# MINI51DE_v1 register map
File version: 1.0
MINI51DE_v1 SVD file
Registers are 32-bit, read-write, reset 0x0 unless marked. A register's access mark holds for its fields unless they carry their own. Offsets are from the block's base; lines under a group give offsets from that group; [hi:lo] are bit positions; {n}, {i} and the like mark numbered series; 'fields as' and 'values as' point back to an identical list; <NAME> marks a mode.

## Memory map
0x40004000 WDT size 0x4 — WDT Register Map
0x40010000 TMR blocks up to offset 0x3C — TMR Register Map
0x40020000 I2C blocks up to offset 0x44 — I2C Register Map
0x40030000 SPI blocks up to offset 0x48 — SPI Register Map
0x40040000 PWM blocks up to offset 0x88 — PWM Register Map
0x40050000 UART size 0x34 — UART Register Map
0x400D0000 ACMP size 0x10 — ACMP Register Map
0x400E0000 ADC blocks up to offset 0x4C — ADC Register Map
0x50000000 GCR blocks up to offset 0x104 — GCR Register Map
0x50000200 CLK blocks up to offset 0x28 — CLK Register Map
0x50000300 INT size 0x88 — INT Register Map
0x50004000 GP blocks up to offset 0x2B8 — GPIO Register Map
0x5000C000 FMC blocks up to offset 0x44 — FMC Register Map
0xE000E000 SCS blocks up to offset 0xD24 — SCS Register Map

## INT — INT Register Map
Base 0x50000300
0x00 IRQ0_SRC ro reset not defined — IRQ0 (BOD) Interrupt Source Identity
  [2:0] INT_SRC — Interrupt Source. Define the interrupt sources for interrupt event.
0x04 IRQ1_SRC ro reset not defined — IRQ1 (WDT) Interrupt Source Identity
  fields as IRQ0_SRC
0x08 IRQ2_SRC ro reset not defined — IRQ2 (EINT0) Interrupt Source Identity
  fields as IRQ0_SRC
0x0C IRQ3_SRC ro reset not defined — IRQ3 (EINT1) Interrupt Source Identity
  fields as IRQ0_SRC
0x10 IRQ4_SRC ro reset not defined — IRQ4 (GP0/1) Interrupt Source Identity
  fields as IRQ0_SRC
0x14 IRQ5_SRC ro reset not defined — IRQ5 (GP2/3/4) Interrupt Source Identity
  fields as IRQ0_SRC
0x18 IRQ6_SRC ro reset not defined — IRQ6 (PWM) Interrupt Source Identity
  fields as IRQ0_SRC
0x1C IRQ7_SRC ro reset not defined — IRQ7 (BRAKE) Interrupt Source Identity
  fields as IRQ0_SRC
0x20 IRQ8_SRC ro reset not defined — IRQ8 (TMR0) Interrupt Source Identity
  fields as IRQ0_SRC
0x24 IRQ9_SRC ro reset not defined — IRQ9 (TMR1) Interrupt Source Identity
  fields as IRQ0_SRC
0x28 IRQ10_SRC ro reset not defined — Reserved
  fields as IRQ0_SRC
0x2C IRQ11_SRC ro reset not defined — Reserved
  fields as IRQ0_SRC
0x30 IRQ12_SRC ro reset not defined — IRQ12 (UART) Interrupt Source Identity
  fields as IRQ0_SRC
0x34 IRQ13_SRC ro reset not defined — Reserved
  fields as IRQ0_SRC
0x38 IRQ14_SRC ro reset not defined — IRQ14 (SPI) Interrupt Source Identity
  fields as IRQ0_SRC
0x3C IRQ15_SRC ro reset not defined — Reserved
  fields as IRQ0_SRC
0x40 IRQ16_SRC ro reset not defined — IRQ16 (GP5) Interrupt Source Identity
  fields as IRQ0_SRC
0x44 IRQ17_SRC ro reset not defined — IRQ17 (HIRC Trim) Interrupt Source Identity
  fields as IRQ0_SRC
0x48 IRQ18_SRC ro reset not defined — IRQ18 (I2C) Interrupt Source Identity
  fields as IRQ0_SRC
{0x0+4i} IRQ{i}_SRC ro reset not defined (i=19..24) — Reserved
  fields as IRQ0_SRC
0x64 IRQ25_SRC ro reset not defined — IRQ25 (ACMP) Interrupt Source Identity
  fields as IRQ0_SRC
0x68 IRQ26_SRC ro reset not defined — Reserved
  fields as IRQ0_SRC
0x6C IRQ27_SRC ro reset not defined — Reserved
  fields as IRQ0_SRC
0x70 IRQ28_SRC ro reset not defined — IRQ28 (PWRWU) Interrupt Source Identity
  fields as IRQ0_SRC
0x74 IRQ29_SRC ro reset not defined — IRQ29 (ADC) Interrupt Source Identity
  fields as IRQ0_SRC
0x78 IRQ30_SRC ro reset not defined — Reserved
  fields as IRQ0_SRC
0x7C IRQ31_SRC ro reset not defined — Reserved
  fields as IRQ0_SRC
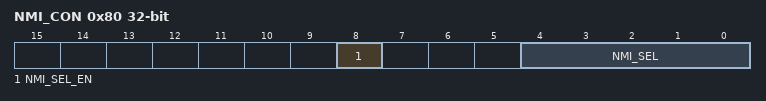
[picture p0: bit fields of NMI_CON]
0x80 NMI_CON — NMI Source Interrupt Select Control Register
  [8] NMI_SEL_EN — NMI Interrupt Enable Control (Write Protect). Note: This bit is the protected bit, and programming it needs to write 0x59, 0x16, and 0x88 to address 0x5000_0100 to disable register protection. Refer to the register REGWRPROT at address GCR_BA+0x100.
    0=NMI interrupt Disabled; 1=NMI interrupt Enabled
  [4:0] NMI_SEL — NMI Interrupt Source Selection. The NMI interrupt to Cortex-M0 can be selected from one of the peripheral interrupt by setting NMI_SEL.
0x84 MCU_IRQ — MCU IRQ Number Identity Register
  [31:0] MCU_IRQ — MCU IRQ Source. The MCU_IRQ collects all the interrupts from the peripherals and generates the synchronous interrupt to Cortex-M0 core. This modes to generate interrupt to Cortex-M0 - the normal mode. The MCU_IRQ collects all interrupts from each peripheral and synchronizes them then interrupts the Cortex-M0. When the MCU_IRQ[n] is 0, setting MCU_IRQ[n] to 1 will generate an interrupt to Cortex-M0 NVIC[n]. When the MCU_IRQ[n] is 1 (mean an interrupt is assert), setting 1 to the MCU_bit[n] will clear the interrupt and setting MCU_IRQ[n] 0 has no effect.
